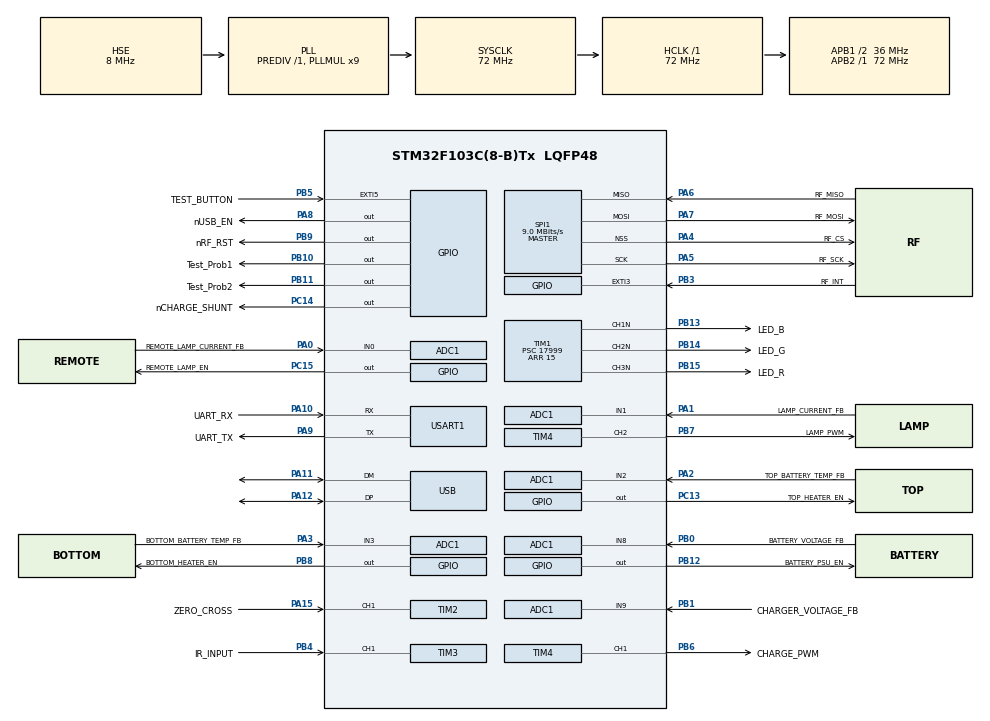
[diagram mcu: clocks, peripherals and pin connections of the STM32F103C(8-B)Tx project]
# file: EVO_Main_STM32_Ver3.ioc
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ADC1.Channel-0\#ChannelRegularConversion=ADC_CHANNEL_0
ADC1.Channel-1\#ChannelRegularConversion=ADC_CHANNEL_1
ADC1.Channel-2\#ChannelRegularConversion=ADC_CHANNEL_2
ADC1.Channel-3\#ChannelRegularConversion=ADC_CHANNEL_3
ADC1.Channel-4\#ChannelRegularConversion=ADC_CHANNEL_8
ADC1.Channel-5\#ChannelRegularConversion=ADC_CHANNEL_9
ADC1.ContinuousConvMode=ENABLE
ADC1.DiscontinuousConvMode=DISABLE
ADC1.NbrOfConversion=6
ADC1.NbrOfConversionFlag=1
ADC1.Rank-0\#ChannelRegularConversion=1
ADC1.Rank-1\#ChannelRegularConversion=2
ADC1.Rank-2\#ChannelRegularConversion=3
ADC1.Rank-3\#ChannelRegularConversion=4
ADC1.Rank-4\#ChannelRegularConversion=5
ADC1.Rank-5\#ChannelRegularConversion=6
ADC1.SamplingTime-0\#ChannelRegularConversion=ADC_SAMPLETIME_55CYCLES_5
ADC1.SamplingTime-1\#ChannelRegularConversion=ADC_SAMPLETIME_55CYCLES_5
ADC1.SamplingTime-2\#ChannelRegularConversion=ADC_SAMPLETIME_55CYCLES_5
ADC1.SamplingTime-3\#ChannelRegularConversion=ADC_SAMPLETIME_55CYCLES_5
ADC1.SamplingTime-4\#ChannelRegularConversion=ADC_SAMPLETIME_55CYCLES_5
ADC1.SamplingTime-5\#ChannelRegularConversion=ADC_SAMPLETIME_55CYCLES_5
ADC1.master=1
Dma.ADC1.0.Direction=DMA_PERIPH_TO_MEMORY
Dma.ADC1.0.Instance=DMA1_Channel1
Dma.ADC1.0.MemDataAlignment=DMA_MDATAALIGN_WORD
Dma.ADC1.0.MemInc=DMA_MINC_ENABLE
Dma.ADC1.0.Mode=DMA_CIRCULAR
Dma.ADC1.0.PeriphDataAlignment=DMA_PDATAALIGN_WORD
Dma.ADC1.0.PeriphInc=DMA_PINC_DISABLE
Dma.ADC1.0.Priority=DMA_PRIORITY_HIGH
Dma.Request0=ADC1
Mcu.Family=STM32F1
Mcu.Name=STM32F103C(8-B)Tx
Mcu.Package=LQFP48
NVIC.EXTI3_IRQn=true\:1\:0\:true\:false\:true\:true\:true\:true
NVIC.EXTI9_5_IRQn=true\:2\:0\:true\:false\:true\:true\:true\:true
NVIC.PriorityGroup=NVIC_PRIORITYGROUP_4
NVIC.TIM2_IRQn=true\:0\:0\:true\:false\:true\:true\:true\:true
NVIC.TIM3_IRQn=true\:1\:0\:true\:false\:true\:true\:true\:true
NVIC.USB_HP_CAN1_TX_IRQn=true\:1\:0\:true\:false\:true\:true\:true\:true
NVIC.USB_LP_CAN1_RX0_IRQn=true\:1\:0\:true\:false\:true\:false\:true\:true
PA0-WKUP.GPIO_Label=REMOTE_LAMP_CURRENT_FB
PA0-WKUP.Signal=ADCx_IN0
PA1.GPIO_Label=LAMP_CURRENT_FB
PA1.Signal=ADCx_IN1
PA10.GPIO_Label=UART_RX
PA10.Mode=Asynchronous
PA10.Signal=USART1_RX
PA11.Mode=Device
PA11.Signal=USB_DM
PA12.Mode=Device
PA12.Signal=USB_DP
PA13.Mode=Serial_Wire
PA13.Signal=SYS_JTMS-SWDIO
PA14.Mode=Serial_Wire
PA14.Signal=SYS_JTCK-SWCLK
PA15.GPIO_Label=ZERO_CROSS
PA15.GPIO_PuPd=GPIO_PULLUP
PA15.Signal=S_TIM2_CH1_ETR
PA2.GPIO_Label=TOP_BATTERY_TEMP_FB
PA2.Signal=ADCx_IN2
PA3.GPIO_Label=BOTTOM_BATTERY_TEMP_FB
PA3.Signal=ADCx_IN3
PA4.GPIO_Label=RF_CS
PA4.Mode=NSS_Signal_Hard_Output
PA4.Signal=SPI1_NSS
PA5.GPIO_Label=RF_SCK
PA5.Mode=Full_Duplex_Master
PA5.Signal=SPI1_SCK
PA6.GPIO_Label=RF_MISO
PA6.Mode=Full_Duplex_Master
PA6.Signal=SPI1_MISO
PA7.GPIO_Label=RF_MOSI
PA7.Mode=Full_Duplex_Master
PA7.Signal=SPI1_MOSI
PA8.GPIO_Label=nUSB_EN
PA8.Signal=GPIO_Output
PA9.GPIO_Label=UART_TX
PA9.Mode=Asynchronous
PA9.Signal=USART1_TX
PB0.GPIO_Label=BATTERY_VOLTAGE_FB
PB0.Signal=ADCx_IN8
PB1.GPIO_Label=CHARGER_VOLTAGE_FB
PB1.Signal=ADCx_IN9
PB10.GPIO_Label=Test_Prob1
PB10.GPIO_Speed=GPIO_SPEED_FREQ_MEDIUM
PB10.Signal=GPIO_Output
PB11.GPIO_Label=Test_Prob2
PB11.GPIO_Speed=GPIO_SPEED_FREQ_MEDIUM
PB11.Signal=GPIO_Output
PB12.GPIO_Label=BATTERY_PSU_EN
PB12.Signal=GPIO_Output
PB13.GPIO_Label=LED_B
PB13.Mode=PWM Generation1 CH1N
PB13.Signal=TIM1_CH1N
PB14.GPIO_Label=LED_G
PB14.Mode=PWM Generation2 CH2N
PB14.Signal=TIM1_CH2N
PB15.GPIO_Label=LED_R
PB15.Mode=PWM Generation3 CH3N
PB15.Signal=TIM1_CH3N
PB3.GPIO_Label=RF_INT
PB3.Signal=GPXTI3
PB4.GPIO_Label=IR_INPUT
PB4.Signal=S_TIM3_CH1
PB5.GPIO_Label=TEST_BUTTON
PB5.GPIO_ModeDefaultEXTI=GPIO_MODE_IT_FALLING
PB5.Signal=GPXTI5
PB6.GPIO_Label=CHARGE_PWM
PB6.GPIO_Speed=GPIO_SPEED_FREQ_MEDIUM
PB6.Signal=S_TIM4_CH1
PB7.GPIO_Label=LAMP_PWM
PB7.GPIO_Speed=GPIO_SPEED_FREQ_MEDIUM
PB7.Signal=S_TIM4_CH2
PB8.GPIO_Label=BOTTOM_HEATER_EN
PB8.Signal=GPIO_Output
PB9.GPIO_Label=nRF_RST
PB9.Signal=GPIO_Output
PC13-TAMPER-RTC.GPIO_Label=TOP_HEATER_EN
PC13-TAMPER-RTC.GPIO_PuPd=GPIO_PULLDOWN
PC13-TAMPER-RTC.Signal=GPIO_Output
PC14-OSC32_IN.GPIO_Label=nCHARGE_SHUNT
PC14-OSC32_IN.GPIO_PuPd=GPIO_PULLDOWN
PC14-OSC32_IN.Signal=GPIO_Output
PC15-OSC32_OUT.GPIO_Label=REMOTE_LAMP_EN
PC15-OSC32_OUT.GPIO_PuPd=GPIO_PULLDOWN
PC15-OSC32_OUT.Signal=GPIO_Output
PD0-OSC_IN.Mode=HSE-External-Oscillator
PD0-OSC_IN.Signal=RCC_OSC_IN
PD1-OSC_OUT.Mode=HSE-External-Oscillator
PD1-OSC_OUT.Signal=RCC_OSC_OUT
ProjectManager.HeapSize=0x200
ProjectManager.StackSize=0x400
ProjectManager.TargetToolchain=MDK-ARM V5
RCC.ADCPresc=RCC_ADCPCLK2_DIV6
RCC.AHBFreq_Value=72000000
RCC.APB1CLKDivider=RCC_HCLK_DIV2
RCC.APB1Freq_Value=36000000
RCC.APB1TimFreq_Value=72000000
RCC.APB2Freq_Value=72000000
RCC.APB2TimFreq_Value=72000000
RCC.HCLKFreq_Value=72000000
RCC.PLLMUL=RCC_PLL_MUL9
RCC.SYSCLKFreq_VALUE=72000000
RCC.SYSCLKSource=RCC_SYSCLKSOURCE_PLLCLK
RCC.USBFreq_Value=48000000
RCC.USBPrescaler=RCC_USBCLKSOURCE_PLL_DIV1_5
SH.ADCx_IN0.0=ADC1_IN0,IN0
SH.ADCx_IN1.0=ADC1_IN1,IN1
SH.ADCx_IN2.0=ADC1_IN2,IN2
SH.ADCx_IN3.0=ADC1_IN3,IN3
SH.ADCx_IN8.0=ADC1_IN8,IN8
SH.ADCx_IN9.0=ADC1_IN9,IN9
SH.S_TIM2_CH1_ETR.0=TIM2_CH1,Input_Capture1_from_TI1
SH.S_TIM3_CH1.0=TIM3_CH1,Input_Capture1_from_TI1
SH.S_TIM4_CH1.0=TIM4_CH1,PWM Generation1 CH1
SH.S_TIM4_CH2.0=TIM4_CH2,PWM Generation2 CH2
SPI1.BaudRatePrescaler=SPI_BAUDRATEPRESCALER_8
SPI1.CalculateBaudRate=9.0 MBits/s
SPI1.Direction=SPI_DIRECTION_2LINES
SPI1.Mode=SPI_MODE_MASTER
SPI1.VirtualNSS=VM_NSSHARD
SPI1.VirtualType=VM_MASTER
TIM1.AutoReloadPreload=TIM_AUTORELOAD_PRELOAD_ENABLE
TIM1.Channel-PWM\ Generation1\ CH1N=TIM_CHANNEL_1
TIM1.Channel-PWM\ Generation2\ CH2N=TIM_CHANNEL_2
TIM1.Channel-PWM\ Generation3\ CH3N=TIM_CHANNEL_3
TIM1.OC1Preload_PWM=ENABLE
TIM1.OCNIdleState_1=TIM_OCNIDLESTATE_SET
TIM1.OCNIdleState_2=TIM_OCNIDLESTATE_SET
TIM1.OCNIdleState_3=TIM_OCNIDLESTATE_SET
TIM1.OCNPolarity_1=TIM_OCNPOLARITY_LOW
TIM1.OCNPolarity_2=TIM_OCNPOLARITY_LOW
TIM1.OCNPolarity_3=TIM_OCNPOLARITY_LOW
TIM1.Period=15
TIM1.Prescaler=17999
TIM2.AutoReloadPreload=TIM_AUTORELOAD_PRELOAD_DISABLE
TIM2.Channel-Input_Capture1_from_TI1=TIM_CHANNEL_1
TIM2.Channel-Input_Capture2_from_TI1_63=TIM_CHANNEL_2
TIM2.ICFilter_CH1=8
TIM2.ICPolarity_CH1=TIM_INPUTCHANNELPOLARITY_FALLING
TIM2.ICPrescaler-Input_Capture1_from_TI1=TIM_ICPSC_DIV1
TIM2.Period=65535
TIM2.Prescaler=143
TIM2.TIM_MasterOutputTrigger=TIM_TRGO_RESET
TIM3.Channel-Input_Capture1_from_TI1=TIM_CHANNEL_1
TIM3.Channel-Input_Capture2_from_TI1_63=TIM_CHANNEL_2
TIM3.ICPolarity_CH1=TIM_INPUTCHANNELPOLARITY_FALLING
TIM3.Period=40000
TIM3.Prescaler=71
TIM4.AutoReloadPreload=TIM_AUTORELOAD_PRELOAD_ENABLE
TIM4.Channel-PWM\ Generation1\ CH1=TIM_CHANNEL_1
TIM4.Channel-PWM\ Generation2\ CH2=TIM_CHANNEL_2
TIM4.OCPolarity_1=TIM_OCPOLARITY_HIGH
TIM4.OCPolarity_2=TIM_OCPOLARITY_HIGH
TIM4.Period=99
TIM4.Prescaler=359
USART1.VirtualMode=VM_ASYNC
USB_DEVICE.CLASS_NAME_FS=CDC
USB_DEVICE.PID_CDC_FS=0x5740
USB_DEVICE.VID=0x483
USB_DEVICE.VirtualMode=Cdc
USB_DEVICE.VirtualModeFS=Cdc_FS
VP_TIM1_VS_ClockSourceINT.Mode=Internal
VP_TIM2_VS_ClockSourceINT.Mode=Internal
VP_TIM2_VS_indirect_ch1.Mode=Input_Capture2_from_TI1_63
VP_TIM3_VS_ClockSourceINT.Mode=Internal
VP_TIM3_VS_indirect_ch1.Mode=Input_Capture2_from_TI1_63
VP_TIM4_VS_ClockSourceINT.Mode=Internal
VP_USB_DEVICE_VS_USB_DEVICE_CDC_FS.Mode=CDC_FS
board=custom

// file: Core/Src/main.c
/* USER CODE BEGIN Header */
/**
  ******************************************************************************
  * @file           : main.c
  * @brief          : Main program body
  ******************************************************************************
  * @attention
  *
  * Copyright (c) 2023 STMicroelectronics.
  * All rights reserved.
  *
  * This software is licensed under terms that can be found in the LICENSE file
  * in the root directory of this software component.
  * If no LICENSE file comes with this software, it is provided AS-IS.
  *
  ******************************************************************************
  */
/* USER CODE END Header */
#include "main.h"
#include "usb_device.h"

/* USER CODE BEGIN Includes */
#include "usbd_cdc_if.h"
#include "Flash_EEPROM.h"
#include "IR_Zero_Cross.h"
#include "Charge.h"
#include "ADC.h"
#include "stm32f1xx_it.h"

//#include "stm32f1xx_hal_tim.h"

/* USER CODE END Includes */

/* USER CODE BEGIN PD */
#define ADDR_FLASH_SECTOR_63     ((uint32_t)0x0800FC00)  /* Base address of Sector 63, 1 Kbytes  */
#define FLASH_MEMORY_ADDR         ADDR_FLASH_SECTOR_63

/*
#define Seconds_Per_Day          	86400         // should be 86400-1 *nan
#define Days_Per_Period           28            // should be 28 days *nan
#define Long_Test_Period_Num 		  13            // should be 13: total of 13 period *nan
*/

#define AC_Fail                  	0
#define AC_Good                 	1
#define Invalid							      2

/* USER CODE END PD */

ADC_HandleTypeDef hadc1;
DMA_HandleTypeDef hdma_adc1;

SPI_HandleTypeDef hspi1;

TIM_HandleTypeDef htim1;
TIM_HandleTypeDef htim2;
TIM_HandleTypeDef htim3;
TIM_HandleTypeDef htim4;

UART_HandleTypeDef huart1;

/* USER CODE BEGIN PV */
extern LED_Profile_TypeDef  *Pointer_Profile_running;

extern uint16_t time_stamp_start;
extern uint16_t Emergency_ElapsedTime;

uint32_t Time_delay_Elapsed;
uint32_t Time_delay_StartTime;

System_State_TypeDef System_State_Machine = STANDBY;

struct sys_time System_time ={0,0,27,0}; // day:27 is for UL test -> 24hours later to start the short test

uint8_t Short_test_En = 0;
uint8_t Long_test_En  = 0;

NV_Profile_TypeDef NV_Profile_Default =
{
  1,
  0x2e782dade227f669,         //signature
  16,             			// Total wattage of the unit, optianl of 16W,32W and 64W(battery realted)
  8,            			// Lamp head wattage: 4W, 8W and 16W
  0,               			// heater installation
  1,						// Self test enable
  0,          			     // Delay after AC resumed, uint: seconds, options - 0s 0r 900s
  0,                          // the last testing failure flag
  200,                        // default lamp current value for the first time programming (4W value)
  200,                        // default lamp current value for the first time programming (4W value)
 };

extern LED_Profile_TypeDef LED_Profile_90M_TEST;
extern LED_Profile_TypeDef LED_Profile_30s_TEST;
extern LED_Profile_TypeDef LED_Profile_Batt_Disconnect;
extern LED_Profile_TypeDef LED_Profile_Charger_Fail;
extern LED_Profile_TypeDef LED_Profile_Lamp_Fail;
extern LED_Profile_TypeDef LED_Profile_Low_Capacity;
extern LED_Profile_TypeDef LED_Profile_Emergency;
extern LED_Profile_TypeDef LED_Profile_Heating;
extern LED_Profile_TypeDef LED_Profile_Fast_Charge;
extern LED_Profile_TypeDef LED_Profile_Full_Float_Charge;

int32_t  ChargerTest_VoltRaised =0;   // voltage increas amount during the testing period
uint8_t  Charg_Current_Percentage =0; // 0-99 for PWM value backup to resume the charging current
extern CHR_TypeDef CHR_Stage;
extern uint32_t Charger_StartTime ;
extern uint32_t Charger_ElapsedTime;
extern uint8_t Charge_rate;

uint32_t ADC_StartTime =0;               // for ADC sampling time gap, unit: millisecond
uint32_t ADC_CurrentTime =0;
uint32_t ADC_ElapsedTime =0;

uint32_t ADC_Local_lamp_FB_init;         //local lamp current measured when power up for diagnostic
uint32_t ADC_Remote_lamp_FB_init;

uint32_t ADC_Local_lamp_FB_reading;      //local lamp current reading when diagnostic
uint32_t ADC_Remote_lamp_FB_reading;

// For diming
uint8_t  Lamp_Diming_level;              // the lamp brightness PWM control for diming, decreaed by 1 on each time
uint8_t  Lamp_Diming_timer;              // the timing for emergency diming time period, diming level decreaes when timer count down to zero
uint8_t  Lamp_Diming_cnt;                // the decreasing times during the diming period of 16 min

uint16_t Lamp_Diming_startTime;
uint8_t  Lamp_Dimng_elapsedTime;

extern uint32_t ADC_batt_reading;
extern uint32_t ADC_charger_reading;

extern uint32_t ADC_DMA_VALUE[6];
extern uint32_t ADC_CHANNCEL_VAL;

extern void ADC_BATT_CHR_ACQ(void);

Heater_state_TypeDef Heater_state[2] = {Heater_Off}; // [0]: buttom heater, [1]: top heater

ButtonPressType_TypeDef TEST_Button = Idle;
//Button_State_TypeDef Button_State = Button_Release;

uint32_t ADC_temp_reading[2];                        // temperature ADC value reading buffer, [0]: buttom , [1]: top

/* USER CODE END PV */

void SystemClock_Config(void);
static void MX_GPIO_Init(void);
static void MX_DMA_Init(void);
static void MX_ADC1_Init(void);
static void MX_SPI1_Init(void);
static void MX_TIM1_Init(void);
static void MX_TIM2_Init(void);
static void MX_TIM3_Init(void);
static void MX_TIM4_Init(void);
static void MX_USART1_UART_Init(void);
/* USER CODE BEGIN PFP */
extern void Flash_write(void);
extern void Flash_read(void);
extern void Flash_clear(void);
extern HAL_StatusTypeDef HAL_TIM_Base_Start_IT(TIM_HandleTypeDef *htim);

NV_Profile_TypeDef NV_Profile_Runtime;

uint32_t time_delta(uint32_t Current_time, uint32_t start_time);  // for calculate the time duration of seconds or minutes

extern void LED_task(LED_Display_TypeDef Display_Type, FunctionalState Enable);
extern void IR_task(void);
extern uint8_t Zero_Cross_Task(void);

/* USER CODE END PFP */

/* USER CODE BEGIN 0 */

//USB init and reset
void USB_Init(void)   // added USB reset
{

    GPIO_InitTypeDef GPIO_InitStruct = {0};
    __HAL_RCC_GPIOA_CLK_ENABLE();

    HAL_GPIO_WritePin(GPIOA,  GPIO_PIN_11 | GPIO_PIN_12, GPIO_PIN_RESET);
    GPIO_InitStruct.Pin = GPIO_PIN_11 | GPIO_PIN_12;
    GPIO_InitStruct.Mode = GPIO_MODE_OUTPUT_PP;
    GPIO_InitStruct.Pull = GPIO_PULLDOWN;
    GPIO_InitStruct.Speed = GPIO_SPEED_FREQ_LOW;
    HAL_GPIO_Init(GPIOA, &GPIO_InitStruct);

    HAL_Delay(20);

}

 uint8_t Remote_Lamp_Flag =0;

// Lamp init

void LAMP_Init(void)
{
  if (ADC_DMA_VALUE[ADC_BATT_VOLTAGE] < V_PreChr )   // under low battery voltage condition, don't read the lamp current, get the saved value from Flash memory instead.
  {
    ADC_Local_lamp_FB_init  = NV_Profile_Runtime.LocalLampCurrentInit;
    ADC_Remote_lamp_FB_init = NV_Profile_Runtime.RemoteLampCurrentInit;
  }
  else                                              // battery voltage is good for lamp initialze,
  {
    Lamp_ctrl(ENABLE, NV_Profile_Runtime.HeadWattage); // turn on local lamp
    Remote_Lamp_EN(ENABLE);                            // turn on remote lamp

    HAL_Delay(1500);         // keep the lamp on for virtual checking

    uint8_t i =0;
    ADC_Local_lamp_FB_init =0;
    for (i=0; i < ADC_slide_windows_size; i++)              // measure local lamp current
    {
      ADC_Local_lamp_FB_init += ADC_DMA_VALUE[ADC_LOCAL_LAMP_CUR];
      HAL_Delay(2);
    }

    ADC_Local_lamp_FB_init = ADC_Local_lamp_FB_init/ADC_slide_windows_size;     //ADC_DMA_VALUE[ADC_LOCAL_LAMP_CUR];
    if (ADC_Local_lamp_FB_init < 120)                                           // 60% of ADC value 200 (4W)
    {
	 ADC_Local_lamp_FB_init = 0; // no lamp detected, clear the current value
    }

    NV_Profile_Runtime.LocalLampCurrentInit = ADC_Local_lamp_FB_init;           // update the flash memory value

    for (i=0; i< ADC_slide_windows_size; i++)              // measure remote lamp current
    {
	 ADC_Remote_lamp_FB_init += ADC_DMA_VALUE[ADC_REMOTE_LAMP_CUR];
	 HAL_Delay(2);
    }
    ADC_Remote_lamp_FB_init = ADC_Remote_lamp_FB_init/ADC_slide_windows_size;  // ADC_DMA_VALUE[ADC_REMOTE_LAMP_CUR];
    if (ADC_Remote_lamp_FB_init < 120)                                         // 60% of ADC value 200 (4W)
    {
	 ADC_Remote_lamp_FB_init = 0;                                             // no lamp detected, clear the current value
    }

    NV_Profile_Runtime.RemoteLampCurrentInit = ADC_Remote_lamp_FB_init;        // update the flash memory value

    Lamp_ctrl(DISABLE, 0);      // turn off the lamps
    Remote_Lamp_EN(DISABLE);
    Flash_write();  // update flasg

  }

/*
	 if (ADC_Local_lamp_FB_init < 150)   // 75% of ADC value 200 (4W)
	 {
	   Local_Lamp_Flag = 0;              // this flag indicate if there is lamp installed-> 0: not installed; 1:installed
	   ADC_Local_lamp_FB_init = 0;
	 }
	 else
	 {
	   Local_Lamp_Flag = 1;
	 }
*/
  if (ADC_Remote_lamp_FB_init < 150)  // 75% of ADC value 200 (4W)
  {
    Remote_Lamp_Flag = 0;             // remote lamp not installed
    ADC_Remote_lamp_FB_init =0;
  }
  else
  {
    Remote_Lamp_Flag = 1;
  }

}

void Charger_Init(void)
{
  uint8_t watt = NV_Profile_Runtime.UnitWattage;

  switch (watt)
  {
    case 16:
    {
      Charge_rate = Chr_Rate_Small_Batt;

      break;
    }
    case 32:
    {
      Charge_rate = Chr_Rate_Big_Batt;

      break;
    }
    case 64:
    {
      Charge_rate = Chr_Rate_Big_Batt *2;

      break;
    }
    default:
      break;
  }

}

/* USER CODE END 0 */

int main(void)
{
// changes test

  /* MCU Configuration--------------------------------------------------------*/

  /* Reset of all peripherals, Initializes the Flash interface and the Systick. */
   HAL_Init();

  /* Configure the system clock */
  SystemClock_Config();

  /* USER CODE BEGIN SysInit */

	 USB_Init();

  /* USER CODE END SysInit */

  /* Initialize all configured peripherals */
  MX_GPIO_Init();
  MX_DMA_Init();
  MX_ADC1_Init();
  MX_SPI1_Init();
  MX_TIM1_Init();
  MX_TIM2_Init();
  MX_TIM3_Init();
  MX_TIM4_Init();
  MX_USB_DEVICE_Init();
  MX_USART1_UART_Init();
  /* USER CODE BEGIN 2 */

// ---------- USB init -----------------

  HAL_GPIO_WritePin(nUSB_EN_GPIO_Port,nUSB_EN_Pin,GPIO_PIN_RESET);              //Enable USB : pull up DP
  HAL_GPIO_WritePin(BATTERY_PSU_EN_GPIO_Port,BATTERY_PSU_EN_Pin,GPIO_PIN_SET);  //Enable battery power

// ------------ LED PWM Init ---------------------

	HAL_TIMEx_PWMN_Start(&htim1,TIM_CHANNEL_1);	//Enable  LED PWM Channels
	HAL_TIMEx_PWMN_Start(&htim1,TIM_CHANNEL_2);
	HAL_TIMEx_PWMN_Start(&htim1,TIM_CHANNEL_3);

//------------- lamp PWM init --------------

  HAL_TIM_PWM_Start(&htim4,TIM_CHANNEL_2);  // Enable Lamp PWM

// ----------- zero cross capture init ----------

    HAL_TIM_Base_Start_IT(&htim2);
    HAL_TIM_IC_Start_IT(&htim2,TIM_CHANNEL_1);  //start zero croess duty cycle capture
		HAL_TIM_IC_Start_IT(&htim2,TIM_CHANNEL_2);

// ----------- IR capture init ----------
		HAL_TIM_Base_Start_IT(&htim3);              // start IR remote capture
    HAL_TIM_IC_Start_IT(&htim3,TIM_CHANNEL_1);
		HAL_TIM_IC_Start_IT(&htim3,TIM_CHANNEL_2);
    HAL_Delay(20);

// ----------- Charge PWM init ----------

    HAL_GPIO_WritePin(nCHARGE_SHUNT_GPIO_Port,nCHARGE_SHUNT_Pin,GPIO_PIN_RESET);  // enable shunt resister
    HAL_TIM_PWM_Start(&htim4,TIM_CHANNEL_1);	                                    //Enable  charge PWM

// ------------ ADC init -------------

	HAL_ADCEx_Calibration_Start(&hadc1);          // ADC calibration
	HAL_ADC_Start_DMA(&hadc1, ADC_DMA_VALUE, 6 ); // start ADC

// load profile

	memcpy (&NV_Profile_Runtime,(uint32_t*)FLASH_MEMORY_ADDR, sizeof(NV_Profile_Runtime)); // load  profile from Flash Memory to ram
	if ( NV_Profile_Runtime.Flag == 0xFF )                    // check if the flash memory is blank
	{
  	  memcpy (&NV_Profile_Runtime, &NV_Profile_Default, sizeof(NV_Profile_Runtime)); //the FLASH is blank, load default and save to the flash, this will occure only the first time running the code at factory
       Flash_write();  // save the profile data from runtime ram to flash
      }

	__HAL_TIM_SetCompare(&htim1, LED_PWM_CH_RED, LED_LUMNOUS);
	__HAL_TIM_SetCompare(&htim1, LED_PWM_CH_GREEN, LED_LUMNOUS);
	__HAL_TIM_SetCompare(&htim1, LED_PWM_CH_BLUE, LED_LUMNOUS);

	ADC_BATT_CHR_ACQ();

	// lamp init, measure the Lamp current as reference for diagnostic
	LAMP_Init();

	if (NV_Profile_Runtime.LastTestFailedFlag == 1)
	{
	  LED_task(Low_Capacity, ENABLE);  // indicate the batter was fail on the last Long Test
	}

     BATT_TEMP_task();

// Charger init, load the charge rate for battery configurations

     Charger_Init();

	CHARGE_task();

  /* USER CODE END 2 */

  /* Infinite loop */
  /* USER CODE BEGIN WHILE */

 while (1)
 {
 /*
	USBVcom_printf("ms: %llu\r\n", System_time.ms);
	HAL_Delay(1);
	USBVcom_printf("Second: %u\r\n", System_time.Sec);
	HAL_Delay(1);
	USBVcom_printf("Day: %hu\r\n\r\n", System_time.Day);
 */

  switch (System_State_Machine)
  {
    case STANDBY:   // standby mode
    {

	 LED_Driver();

	 if (Zero_Cross_Task() == AC_Fail )
	 {

	   Lamp_ctrl(ENABLE, NV_Profile_Runtime.HeadWattage);
	   Remote_Lamp_EN(ENABLE);

	   HAL_Delay(200);

	   time_stamp_start = System_time.Sec; // emergency timer start
	   System_State_Machine = EMERGENCY;   // has to excute this before disable the heaters for proventing the heater state machine go into the heating stage

	   LED_task(Emergency, ENABLE);
	   ADC_StartTime = HAL_GetTick();     // start ADC timer
	   Charger_ElapsedTime =0;

        break;
	 }

	 BATT_TEMP_task();   // check the battery temperature, has to be done prior to the CHARGE_Task because it need to report the temperature that used for Charge

      ADC_BATT_CHR_ACQ();

	 CHARGE_task();      // check and auto control the battery charge

	 HEATER_task();
	 Button_task();      // check the button and start the test mode

	 if (NV_Profile_Runtime.SelfDiagnosticEnabled != 0)
	 {
	   Scheduler_task();
	 }

	 IR_task();          // check the IR remote command

	 break;
    }

    case EMERGENCY:
    {
	 ADC_ElapsedTime = ElapsedTimer_ADC(ADC_StartTime);           // ADC timing
      if(System_time.Sec < time_stamp_start)                       // Emergency duration timing
	 {
	   Emergency_ElapsedTime = UINT32_MAX/1000 + System_time.Sec - time_stamp_start +1;
	 }
	 else
	 {
	   Emergency_ElapsedTime = System_time.Sec - time_stamp_start;
	 }

	 if (( (ADC_ElapsedTime)%1500 == 0) && ADC_ElapsedTime > 1499)   //every 1.5s to read the ADC
	 {
//	   ADC_batt_reading = ADC_DMA_VALUE[ADC_BATT_VOLTAGE];

	   if ( ADC_batt_reading < V_Low_Temp )
	   {
	    Lamp_ctrl(DISABLE, 0);                                                          // turn off the MCU and the lamps when the battery is too low
	    HAL_GPIO_WritePin(BATTERY_PSU_EN_GPIO_Port,BATTERY_PSU_EN_Pin,GPIO_PIN_RESET);  //Disable power from battery to system
	   }

	   ADC_StartTime = HAL_GetTick() ;   //reload the start time for the next 1.5 Sec delay
	 }

	 Lamp_Diming();

      if (Zero_Cross_Task() == AC_Good )
	 {
        Time_delay_Elapsed = ElapsedTimer_TimeDelay( Time_delay_StartTime );;
//	   ADC_batt_reading = ADC_DMA_VALUE[ADC_BATT_VOLTAGE]; //

	   if( Time_delay_Elapsed > NV_Profile_Runtime.TimeDelayPeriod)
	   {
	     Lamp_ctrl(DISABLE, 0);                               // turn off the lamps return to standby
  	     Remote_Lamp_EN(DISABLE);

          LED_task(Emergency, DISABLE);
          CHR_Stage = IDL_CHR;

	     if ((Short_test_En == 1) || ( Long_test_En == 1))   //  when emergency duration is over the short test or long test schedule, delay 1 day.
	     {
		  System_time.Sec = 0;
		  System_time.Day = 27;
		  Short_test_En = 0;
		  Long_test_En = 0;
	     }

	     System_State_Machine = STANDBY;
	     HAL_Delay(10);
	     Charger_ElapsedTime = 0;
	     Charger_StartTime = HAL_GetTick();        //load the start time for the charger timer

	     break;
        }
	 }
	 else Time_delay_StartTime = HAL_GetTick(); // reset the start time of the Time_Delay timer

	 ADC_BATT_CHR_ACQ();
	 CHARGE_task();
	 LED_Driver();
	 break;
    }

    case SHORT_TEST:
    {
      ADC_ElapsedTime = ElapsedTimer_ADC(ADC_StartTime);
      ADC_BATT_CHR_ACQ();

	 if (( (ADC_ElapsedTime%1000) <= 9) && ADC_ElapsedTime > 950)   //every 1.0s to measure the ADC
	 {
	   if ( ADC_batt_reading < V_PreChr)                //
	   {
		 LED_task(Batt_Disconnect, ENABLE);
	   }
	   else
	   {
		 LED_task(Batt_Disconnect, DISABLE);

		 ADC_Local_lamp_FB_reading = ADC_DMA_VALUE[ADC_LOCAL_LAMP_CUR];

		 ADC_Remote_lamp_FB_reading = ADC_DMA_VALUE[ADC_REMOTE_LAMP_CUR];

		 if ( ADC_batt_reading < V_PreChr)      // turn off the lamps when the battery is dead
		 {
		   LED_task(Batt_Disconnect, ENABLE);
		 }

		 if ( (ADC_Local_lamp_FB_reading < (3*ADC_Local_lamp_FB_init/4)) || (ADC_Remote_lamp_FB_reading < (3*ADC_Remote_lamp_FB_init/4)) ) // check if the current is greater than 75% of the normal lamp current
		 {
		   LED_task(Lamp_Fail, ENABLE);
		 }
		 else
		 {
		   LED_task(Lamp_Fail, DISABLE);
		 }
	   }

	   ADC_StartTime = HAL_GetTick() ;   //reload the start time for the nest 2s delay
	 }

	 if( time_delta(System_time.Sec,time_stamp_start) >= 30 )                    // 30 for 30 second test
	 {
	   Lamp_ctrl(DISABLE, 0);  // turn off the lamps return to standby
  	   Remote_Lamp_EN(DISABLE);
	   TEST_Button = Idle;

	   LED_task(_30s_TEST, DISABLE);
	   Charger_ElapsedTime = 0;
	   System_State_Machine = STANDBY;
	 }

	 CHARGE_task();
      IR_task();

	 Button_task();
	 LED_Driver();

	 break;
    }

    case LONG_TEST:
    {
	 ADC_ElapsedTime = ElapsedTimer_ADC(ADC_StartTime);
	 if(System_time.Sec < time_stamp_start)                       // Long test duration timing using the emergency timer
	 {
	   Emergency_ElapsedTime = UINT32_MAX/1000 + System_time.Sec - time_stamp_start +1;
	 }
	 else
	 {
	   Emergency_ElapsedTime = System_time.Sec - time_stamp_start;
	 }

	 if (( (ADC_ElapsedTime%1000) <= 9) && ADC_ElapsedTime > 950)   //every 1.0s to measure the ADC
	 {
	   if ( ADC_batt_reading < V_PreChr)                //
	   {
		 LED_task(Batt_Disconnect, ENABLE);
	   }
	   else
	   {
		 LED_task(Batt_Disconnect, DISABLE);

		 ADC_Local_lamp_FB_reading = ADC_DMA_VALUE[ADC_LOCAL_LAMP_CUR];  // read the lamp current from ADC
		 if (Emergency_ElapsedTime < DIMING_START_TIME )                 // before diming start, take 75% for the check threshold
		 {
		   if( ADC_Local_lamp_FB_reading < (3*ADC_Local_lamp_FB_init/4))   // check to see if the current is greater than 75% of the normal lamp current
			  LED_task(Lamp_Fail, ENABLE);
		   else
			  LED_task(Lamp_Fail, DISABLE);
		 }
		 else // after the diming started, take 50% for the check threshold
		 {
		   if(ADC_Local_lamp_FB_reading < (ADC_Local_lamp_FB_init/2))   // check to see if the current is greater than 50% of the normal lamp current
			 LED_task(Lamp_Fail, ENABLE);
		   else
			 LED_task(Lamp_Fail, DISABLE);
		 }

		 ADC_Remote_lamp_FB_reading = ADC_DMA_VALUE[ADC_REMOTE_LAMP_CUR]; // read the lamp current from ADC
		 if (Emergency_ElapsedTime < DIMING_START_TIME )                  // before diming start, take 75% for the check threshold
		 {
		   if( ADC_Remote_lamp_FB_reading < (3*ADC_Remote_lamp_FB_init/4))
		       LED_task(Lamp_Fail, ENABLE);
		   else
			  LED_task(Lamp_Fail, DISABLE);
		 }
		 else  // after the diming started, take 50% for the check threshold
		 {
		   if ( ADC_Remote_lamp_FB_reading < (ADC_Remote_lamp_FB_init/2)) // check to see if the current is greater than 50% of the normal lamp current
			   LED_task(Lamp_Fail, ENABLE);
		   else
			   LED_task(Lamp_Fail, DISABLE);
		 }

        }

	   ADC_StartTime = HAL_GetTick() ;   //reset the start time for the next 1s delay
	 }

	 if ( ADC_batt_reading < V_Low_Capacity )  // fail the 90M test before the 90M is due
	 {
	   Lamp_ctrl(DISABLE, 0);  // turn off the lamps return to standby
  	   Remote_Lamp_EN(DISABLE);

	   TEST_Button = Idle;
	   LED_task(Low_Capacity, ENABLE);
	   LED_task(_90M_TEST, DISABLE);
	   System_State_Machine = STANDBY;
      }
      else
	 {                                                                                 // pass the 90M test
	   if (time_delta(System_time.Sec, time_stamp_start) >= 5400)                      // should be 5400 for 90min test *nan
	   {
		Lamp_ctrl(DISABLE, 0);  // turn off the lamps return to standby
  	     Remote_Lamp_EN(DISABLE);

          TEST_Button = Idle;
		NV_Profile_Runtime.LastTestFailedFlag = 0;                                  //clear the fail flag
		Flash_write();

		LED_task(_90M_TEST, DISABLE);
		System_State_Machine = STANDBY;
	   }

	 }

	 Lamp_Diming();

      ADC_BATT_CHR_ACQ();
	 CHARGE_task();
	 IR_task();
	 Button_task();
	 LED_Driver();

	 break;
    }

    case EOL:
    {
	 break;
    }

    case DEMO:
    {

	 LED_Driver();
	 BATT_TEMP_task();   // check the battery temperature, has to be done prior to the CHARGE_Task because it need to report the temperature that used for Charge
      ADC_BATT_CHR_ACQ();

	 HEATER_task();

	 CHARGE_task();      // check and auto control the battery charge

	 Button_task();      // check the button and start the test mode
	 IR_task();
  	 break;
    }

    case SHIP:
    {

	 break;
    }

    default: break;
  }

// -------------------

	//	  USBVcom_printf("Freq:%f\r\n", AC_Freq);
//			USBVcom_printf("Duty:%f\r\n\r\n", Duty_Cycle);
//    printf("Duty:%.2f %% \r\n",(float)Duty_Cycle);
//		printf("Freq:%u\r\n", AC_Freq);

    /* USER CODE END WHILE */

  }
}

void SystemClock_Config(void)
{
  RCC_OscInitTypeDef RCC_OscInitStruct = {0};
  RCC_ClkInitTypeDef RCC_ClkInitStruct = {0};
  RCC_PeriphCLKInitTypeDef PeriphClkInit = {0};

  /** Initializes the RCC Oscillators according to the specified parameters
  * in the RCC_OscInitTypeDef structure.
  */
  RCC_OscInitStruct.OscillatorType = RCC_OSCILLATORTYPE_HSE;
  RCC_OscInitStruct.HSEState = RCC_HSE_ON;
  RCC_OscInitStruct.HSEPredivValue = RCC_HSE_PREDIV_DIV1;
  RCC_OscInitStruct.HSIState = RCC_HSI_ON;
  RCC_OscInitStruct.PLL.PLLState = RCC_PLL_ON;
  RCC_OscInitStruct.PLL.PLLSource = RCC_PLLSOURCE_HSE;
  RCC_OscInitStruct.PLL.PLLMUL = RCC_PLL_MUL9;
  if (HAL_RCC_OscConfig(&RCC_OscInitStruct) != HAL_OK)
  {
    Error_Handler();
  }

  /** Initializes the CPU, AHB and APB buses clocks
  */
  RCC_ClkInitStruct.ClockType = RCC_CLOCKTYPE_HCLK|RCC_CLOCKTYPE_SYSCLK
                              |RCC_CLOCKTYPE_PCLK1|RCC_CLOCKTYPE_PCLK2;
  RCC_ClkInitStruct.SYSCLKSource = RCC_SYSCLKSOURCE_PLLCLK;
  RCC_ClkInitStruct.AHBCLKDivider = RCC_SYSCLK_DIV1;
  RCC_ClkInitStruct.APB1CLKDivider = RCC_HCLK_DIV2;
  RCC_ClkInitStruct.APB2CLKDivider = RCC_HCLK_DIV1;

  if (HAL_RCC_ClockConfig(&RCC_ClkInitStruct, FLASH_LATENCY_2) != HAL_OK)
  {
    Error_Handler();
  }
  PeriphClkInit.PeriphClockSelection = RCC_PERIPHCLK_ADC|RCC_PERIPHCLK_USB;
  PeriphClkInit.AdcClockSelection = RCC_ADCPCLK2_DIV6;
  PeriphClkInit.UsbClockSelection = RCC_USBCLKSOURCE_PLL_DIV1_5;
  if (HAL_RCCEx_PeriphCLKConfig(&PeriphClkInit) != HAL_OK)
  {
    Error_Handler();
  }
}

static void MX_ADC1_Init(void)
{

  ADC_ChannelConfTypeDef sConfig = {0};

  /** Common config
  */
  hadc1.Instance = ADC1;
  hadc1.Init.ScanConvMode = ADC_SCAN_ENABLE;
  hadc1.Init.ContinuousConvMode = ENABLE;
  hadc1.Init.DiscontinuousConvMode = DISABLE;
  hadc1.Init.ExternalTrigConv = ADC_SOFTWARE_START;
  hadc1.Init.DataAlign = ADC_DATAALIGN_RIGHT;
  hadc1.Init.NbrOfConversion = 6;
  if (HAL_ADC_Init(&hadc1) != HAL_OK)
  {
    Error_Handler();
  }

  /** Configure Regular Channel
  */
  sConfig.Channel = ADC_CHANNEL_0;
  sConfig.Rank = ADC_REGULAR_RANK_1;
  sConfig.SamplingTime = ADC_SAMPLETIME_55CYCLES_5;
  if (HAL_ADC_ConfigChannel(&hadc1, &sConfig) != HAL_OK)
  {
    Error_Handler();
  }

  /** Configure Regular Channel
  */
  sConfig.Channel = ADC_CHANNEL_1;
  sConfig.Rank = ADC_REGULAR_RANK_2;
  if (HAL_ADC_ConfigChannel(&hadc1, &sConfig) != HAL_OK)
  {
    Error_Handler();
  }

  /** Configure Regular Channel
  */
  sConfig.Channel = ADC_CHANNEL_2;
  sConfig.Rank = ADC_REGULAR_RANK_3;
  if (HAL_ADC_ConfigChannel(&hadc1, &sConfig) != HAL_OK)
  {
    Error_Handler();
  }

  /** Configure Regular Channel
  */
  sConfig.Channel = ADC_CHANNEL_3;
  sConfig.Rank = ADC_REGULAR_RANK_4;
  if (HAL_ADC_ConfigChannel(&hadc1, &sConfig) != HAL_OK)
  {
    Error_Handler();
  }

  /** Configure Regular Channel
  */
  sConfig.Channel = ADC_CHANNEL_8;
  sConfig.Rank = ADC_REGULAR_RANK_5;
  if (HAL_ADC_ConfigChannel(&hadc1, &sConfig) != HAL_OK)
  {
    Error_Handler();
  }

  /** Configure Regular Channel
  */
  sConfig.Channel = ADC_CHANNEL_9;
  sConfig.Rank = ADC_REGULAR_RANK_6;
  if (HAL_ADC_ConfigChannel(&hadc1, &sConfig) != HAL_OK)
  {
    Error_Handler();
  }

}

static void MX_SPI1_Init(void)
{

  /* SPI1 parameter configuration*/
  hspi1.Instance = SPI1;
  hspi1.Init.Mode = SPI_MODE_MASTER;
  hspi1.Init.Direction = SPI_DIRECTION_2LINES;
  hspi1.Init.DataSize = SPI_DATASIZE_8BIT;
  hspi1.Init.CLKPolarity = SPI_POLARITY_LOW;
  hspi1.Init.CLKPhase = SPI_PHASE_1EDGE;
  hspi1.Init.NSS = SPI_NSS_HARD_OUTPUT;
  hspi1.Init.BaudRatePrescaler = SPI_BAUDRATEPRESCALER_8;
  hspi1.Init.FirstBit = SPI_FIRSTBIT_MSB;
  hspi1.Init.TIMode = SPI_TIMODE_DISABLE;
  hspi1.Init.CRCCalculation = SPI_CRCCALCULATION_DISABLE;
  hspi1.Init.CRCPolynomial = 10;
  if (HAL_SPI_Init(&hspi1) != HAL_OK)
  {
    Error_Handler();
  }

}

static void MX_TIM1_Init(void)
{

  TIM_ClockConfigTypeDef sClockSourceConfig = {0};
  TIM_MasterConfigTypeDef sMasterConfig = {0};
  TIM_OC_InitTypeDef sConfigOC = {0};
  TIM_BreakDeadTimeConfigTypeDef sBreakDeadTimeConfig = {0};

  htim1.Instance = TIM1;
  htim1.Init.Prescaler = 17999;
  htim1.Init.CounterMode = TIM_COUNTERMODE_UP;
  htim1.Init.Period = 15;
  htim1.Init.ClockDivision = TIM_CLOCKDIVISION_DIV1;
  htim1.Init.RepetitionCounter = 0;
  htim1.Init.AutoReloadPreload = TIM_AUTORELOAD_PRELOAD_ENABLE;
  if (HAL_TIM_Base_Init(&htim1) != HAL_OK)
  {
    Error_Handler();
  }
  sClockSourceConfig.ClockSource = TIM_CLOCKSOURCE_INTERNAL;
  if (HAL_TIM_ConfigClockSource(&htim1, &sClockSourceConfig) != HAL_OK)
  {
    Error_Handler();
  }
  if (HAL_TIM_PWM_Init(&htim1) != HAL_OK)
  {
    Error_Handler();
  }
  sMasterConfig.MasterOutputTrigger = TIM_TRGO_RESET;
  sMasterConfig.MasterSlaveMode = TIM_MASTERSLAVEMODE_DISABLE;
  if (HAL_TIMEx_MasterConfigSynchronization(&htim1, &sMasterConfig) != HAL_OK)
  {
    Error_Handler();
  }
  sConfigOC.OCMode = TIM_OCMODE_PWM1;
  sConfigOC.Pulse = 0;
  sConfigOC.OCPolarity = TIM_OCPOLARITY_HIGH;
  sConfigOC.OCNPolarity = TIM_OCNPOLARITY_LOW;
  sConfigOC.OCFastMode = TIM_OCFAST_DISABLE;
  sConfigOC.OCIdleState = TIM_OCIDLESTATE_RESET;
  sConfigOC.OCNIdleState = TIM_OCNIDLESTATE_SET;
  if (HAL_TIM_PWM_ConfigChannel(&htim1, &sConfigOC, TIM_CHANNEL_1) != HAL_OK)
  {
    Error_Handler();
  }
  if (HAL_TIM_PWM_ConfigChannel(&htim1, &sConfigOC, TIM_CHANNEL_2) != HAL_OK)
  {
    Error_Handler();
  }
  if (HAL_TIM_PWM_ConfigChannel(&htim1, &sConfigOC, TIM_CHANNEL_3) != HAL_OK)
  {
    Error_Handler();
  }
  sBreakDeadTimeConfig.OffStateRunMode = TIM_OSSR_DISABLE;
  sBreakDeadTimeConfig.OffStateIDLEMode = TIM_OSSI_DISABLE;
  sBreakDeadTimeConfig.LockLevel = TIM_LOCKLEVEL_OFF;
  sBreakDeadTimeConfig.DeadTime = 0;
  sBreakDeadTimeConfig.BreakState = TIM_BREAK_DISABLE;
  sBreakDeadTimeConfig.BreakPolarity = TIM_BREAKPOLARITY_HIGH;
  sBreakDeadTimeConfig.AutomaticOutput = TIM_AUTOMATICOUTPUT_DISABLE;
  if (HAL_TIMEx_ConfigBreakDeadTime(&htim1, &sBreakDeadTimeConfig) != HAL_OK)
  {
    Error_Handler();
  }
  HAL_TIM_MspPostInit(&htim1);

}

static void MX_TIM2_Init(void)
{

  TIM_ClockConfigTypeDef sClockSourceConfig = {0};
  TIM_MasterConfigTypeDef sMasterConfig = {0};
  TIM_IC_InitTypeDef sConfigIC = {0};

  htim2.Instance = TIM2;
  htim2.Init.Prescaler = 143;
  htim2.Init.CounterMode = TIM_COUNTERMODE_UP;
  htim2.Init.Period = 65535;
  htim2.Init.ClockDivision = TIM_CLOCKDIVISION_DIV1;
  htim2.Init.AutoReloadPreload = TIM_AUTORELOAD_PRELOAD_DISABLE;
  if (HAL_TIM_Base_Init(&htim2) != HAL_OK)
  {
    Error_Handler();
  }
  sClockSourceConfig.ClockSource = TIM_CLOCKSOURCE_INTERNAL;
  if (HAL_TIM_ConfigClockSource(&htim2, &sClockSourceConfig) != HAL_OK)
  {
    Error_Handler();
  }
  if (HAL_TIM_IC_Init(&htim2) != HAL_OK)
  {
    Error_Handler();
  }
  sMasterConfig.MasterOutputTrigger = TIM_TRGO_RESET;
  sMasterConfig.MasterSlaveMode = TIM_MASTERSLAVEMODE_DISABLE;
  if (HAL_TIMEx_MasterConfigSynchronization(&htim2, &sMasterConfig) != HAL_OK)
  {
    Error_Handler();
  }
  sConfigIC.ICPolarity = TIM_INPUTCHANNELPOLARITY_FALLING;
  sConfigIC.ICSelection = TIM_ICSELECTION_DIRECTTI;
  sConfigIC.ICPrescaler = TIM_ICPSC_DIV1;
  sConfigIC.ICFilter = 8;
  if (HAL_TIM_IC_ConfigChannel(&htim2, &sConfigIC, TIM_CHANNEL_1) != HAL_OK)
  {
    Error_Handler();
  }
  sConfigIC.ICPolarity = TIM_INPUTCHANNELPOLARITY_RISING;
  sConfigIC.ICSelection = TIM_ICSELECTION_INDIRECTTI;
  sConfigIC.ICFilter = 0;
  if (HAL_TIM_IC_ConfigChannel(&htim2, &sConfigIC, TIM_CHANNEL_2) != HAL_OK)
  {
    Error_Handler();
  }

}

static void MX_TIM3_Init(void)
{

  TIM_ClockConfigTypeDef sClockSourceConfig = {0};
  TIM_MasterConfigTypeDef sMasterConfig = {0};
  TIM_IC_InitTypeDef sConfigIC = {0};

  htim3.Instance = TIM3;
  htim3.Init.Prescaler = 71;
  htim3.Init.CounterMode = TIM_COUNTERMODE_UP;
  htim3.Init.Period = 40000;
  htim3.Init.ClockDivision = TIM_CLOCKDIVISION_DIV1;
  htim3.Init.AutoReloadPreload = TIM_AUTORELOAD_PRELOAD_DISABLE;
  if (HAL_TIM_Base_Init(&htim3) != HAL_OK)
  {
    Error_Handler();
  }
  sClockSourceConfig.ClockSource = TIM_CLOCKSOURCE_INTERNAL;
  if (HAL_TIM_ConfigClockSource(&htim3, &sClockSourceConfig) != HAL_OK)
  {
    Error_Handler();
  }
  if (HAL_TIM_IC_Init(&htim3) != HAL_OK)
  {
    Error_Handler();
  }
  sMasterConfig.MasterOutputTrigger = TIM_TRGO_RESET;
  sMasterConfig.MasterSlaveMode = TIM_MASTERSLAVEMODE_DISABLE;
  if (HAL_TIMEx_MasterConfigSynchronization(&htim3, &sMasterConfig) != HAL_OK)
  {
    Error_Handler();
  }
  sConfigIC.ICPolarity = TIM_INPUTCHANNELPOLARITY_FALLING;
  sConfigIC.ICSelection = TIM_ICSELECTION_DIRECTTI;
  sConfigIC.ICPrescaler = TIM_ICPSC_DIV1;
  sConfigIC.ICFilter = 0;
  if (HAL_TIM_IC_ConfigChannel(&htim3, &sConfigIC, TIM_CHANNEL_1) != HAL_OK)
  {
    Error_Handler();
  }
  sConfigIC.ICPolarity = TIM_INPUTCHANNELPOLARITY_RISING;
  sConfigIC.ICSelection = TIM_ICSELECTION_INDIRECTTI;
  if (HAL_TIM_IC_ConfigChannel(&htim3, &sConfigIC, TIM_CHANNEL_2) != HAL_OK)
  {
    Error_Handler();
  }

}

static void MX_TIM4_Init(void)
{

  TIM_ClockConfigTypeDef sClockSourceConfig = {0};
  TIM_MasterConfigTypeDef sMasterConfig = {0};
  TIM_OC_InitTypeDef sConfigOC = {0};

  htim4.Instance = TIM4;
  htim4.Init.Prescaler = 359;
  htim4.Init.CounterMode = TIM_COUNTERMODE_UP;
  htim4.Init.Period = 99;
  htim4.Init.ClockDivision = TIM_CLOCKDIVISION_DIV1;
  htim4.Init.AutoReloadPreload = TIM_AUTORELOAD_PRELOAD_ENABLE;
  if (HAL_TIM_Base_Init(&htim4) != HAL_OK)
  {
    Error_Handler();
  }
  sClockSourceConfig.ClockSource = TIM_CLOCKSOURCE_INTERNAL;
  if (HAL_TIM_ConfigClockSource(&htim4, &sClockSourceConfig) != HAL_OK)
  {
    Error_Handler();
  }
  if (HAL_TIM_PWM_Init(&htim4) != HAL_OK)
  {
    Error_Handler();
  }
  sMasterConfig.MasterOutputTrigger = TIM_TRGO_RESET;
  sMasterConfig.MasterSlaveMode = TIM_MASTERSLAVEMODE_DISABLE;
  if (HAL_TIMEx_MasterConfigSynchronization(&htim4, &sMasterConfig) != HAL_OK)
  {
    Error_Handler();
  }
  sConfigOC.OCMode = TIM_OCMODE_PWM1;
  sConfigOC.Pulse = 0;
  sConfigOC.OCPolarity = TIM_OCPOLARITY_HIGH;
  sConfigOC.OCFastMode = TIM_OCFAST_DISABLE;
  if (HAL_TIM_PWM_ConfigChannel(&htim4, &sConfigOC, TIM_CHANNEL_1) != HAL_OK)
  {
    Error_Handler();
  }
  if (HAL_TIM_PWM_ConfigChannel(&htim4, &sConfigOC, TIM_CHANNEL_2) != HAL_OK)
  {
    Error_Handler();
  }
  HAL_TIM_MspPostInit(&htim4);

}

static void MX_USART1_UART_Init(void)
{

  huart1.Instance = USART1;
  huart1.Init.BaudRate = 115200;
  huart1.Init.WordLength = UART_WORDLENGTH_8B;
  huart1.Init.StopBits = UART_STOPBITS_1;
  huart1.Init.Parity = UART_PARITY_NONE;
  huart1.Init.Mode = UART_MODE_TX_RX;
  huart1.Init.HwFlowCtl = UART_HWCONTROL_NONE;
  huart1.Init.OverSampling = UART_OVERSAMPLING_16;
  if (HAL_UART_Init(&huart1) != HAL_OK)
  {
    Error_Handler();
  }

}

static void MX_DMA_Init(void)
{

  /* DMA controller clock enable */
  __HAL_RCC_DMA1_CLK_ENABLE();

}

static void MX_GPIO_Init(void)
{
  GPIO_InitTypeDef GPIO_InitStruct = {0};

  /* GPIO Ports Clock Enable */
  __HAL_RCC_GPIOC_CLK_ENABLE();
  __HAL_RCC_GPIOD_CLK_ENABLE();
  __HAL_RCC_GPIOA_CLK_ENABLE();
  __HAL_RCC_GPIOB_CLK_ENABLE();

  /*Configure GPIO pin Output Level */
  HAL_GPIO_WritePin(GPIOC, TOP_HEATER_EN_Pin|nCHARGE_SHUNT_Pin|REMOTE_LAMP_EN_Pin, GPIO_PIN_RESET);

  /*Configure GPIO pin Output Level */
  HAL_GPIO_WritePin(GPIOB, Test_Prob1_Pin|Test_Prob2_Pin|BATTERY_PSU_EN_Pin|BOTTOM_HEATER_EN_Pin
                          |nRF_RST_Pin, GPIO_PIN_RESET);

  /*Configure GPIO pin Output Level */
  HAL_GPIO_WritePin(nUSB_EN_GPIO_Port, nUSB_EN_Pin, GPIO_PIN_RESET);

  /*Configure GPIO pins : TOP_HEATER_EN_Pin nCHARGE_SHUNT_Pin REMOTE_LAMP_EN_Pin */
  GPIO_InitStruct.Pin = TOP_HEATER_EN_Pin|nCHARGE_SHUNT_Pin|REMOTE_LAMP_EN_Pin;
  GPIO_InitStruct.Mode = GPIO_MODE_OUTPUT_PP;
  GPIO_InitStruct.Pull = GPIO_PULLDOWN;
  GPIO_InitStruct.Speed = GPIO_SPEED_FREQ_LOW;
  HAL_GPIO_Init(GPIOC, &GPIO_InitStruct);

  /*Configure GPIO pins : Test_Prob1_Pin Test_Prob2_Pin */
  GPIO_InitStruct.Pin = Test_Prob1_Pin|Test_Prob2_Pin;
  GPIO_InitStruct.Mode = GPIO_MODE_OUTPUT_PP;
  GPIO_InitStruct.Pull = GPIO_NOPULL;
  GPIO_InitStruct.Speed = GPIO_SPEED_FREQ_MEDIUM;
  HAL_GPIO_Init(GPIOB, &GPIO_InitStruct);

  /*Configure GPIO pins : BATTERY_PSU_EN_Pin BOTTOM_HEATER_EN_Pin nRF_RST_Pin */
  GPIO_InitStruct.Pin = BATTERY_PSU_EN_Pin|BOTTOM_HEATER_EN_Pin|nRF_RST_Pin;
  GPIO_InitStruct.Mode = GPIO_MODE_OUTPUT_PP;
  GPIO_InitStruct.Pull = GPIO_NOPULL;
  GPIO_InitStruct.Speed = GPIO_SPEED_FREQ_LOW;
  HAL_GPIO_Init(GPIOB, &GPIO_InitStruct);

  /*Configure GPIO pin : nUSB_EN_Pin */
  GPIO_InitStruct.Pin = nUSB_EN_Pin;
  GPIO_InitStruct.Mode = GPIO_MODE_OUTPUT_PP;
  GPIO_InitStruct.Pull = GPIO_NOPULL;
  GPIO_InitStruct.Speed = GPIO_SPEED_FREQ_LOW;
  HAL_GPIO_Init(nUSB_EN_GPIO_Port, &GPIO_InitStruct);

  /*Configure GPIO pin : RF_INT_Pin */
  GPIO_InitStruct.Pin = RF_INT_Pin;
  GPIO_InitStruct.Mode = GPIO_MODE_IT_RISING;
  GPIO_InitStruct.Pull = GPIO_NOPULL;
  HAL_GPIO_Init(RF_INT_GPIO_Port, &GPIO_InitStruct);

  /*Configure GPIO pin : TEST_BUTTON_Pin */
  GPIO_InitStruct.Pin = TEST_BUTTON_Pin;
  GPIO_InitStruct.Mode = GPIO_MODE_IT_FALLING;
  GPIO_InitStruct.Pull = GPIO_NOPULL;
  HAL_GPIO_Init(TEST_BUTTON_GPIO_Port, &GPIO_InitStruct);

  /* EXTI interrupt init*/
  HAL_NVIC_SetPriority(EXTI3_IRQn, 1, 0);
  HAL_NVIC_EnableIRQ(EXTI3_IRQn);

  HAL_NVIC_SetPriority(EXTI9_5_IRQn, 2, 0);
  HAL_NVIC_EnableIRQ(EXTI9_5_IRQn);

}

/* USER CODE BEGIN 4 */

// For local LAMP

void Lamp_ctrl(FunctionalState EN, uint8_t LAMP_WATT)
{
  if (EN != 0)
  {
	uint8_t walt = LAMP_WATT;
	uint8_t lamp_level;
	uint8_t i;
	switch (walt)
	{
	  case 0:      {lamp_level = 0;               break;}
	  case _4W: 	{lamp_level = LAMP_LEVEL_4W;   break;}
	  case _8W: 	{lamp_level = LAMP_LEVEL_8W;   break;}
	  case _16W: 	{lamp_level = LAMP_LEVEL_16W;  break;}
	  default:     {                              break;}
	}

	Lamp_Diming_cnt = lamp_level*4/10;        // calculate that how many times the diming operation will decrease the PWM level on 60% final level
	Lamp_Diming_timer = 180/Lamp_Diming_cnt;	 // the total diming period elapsed 3min(180s), calculate the diming will decrese the level by 1
	Lamp_Diming_level =	lamp_level;               // load the initial lamp level value to diming control variable

	HAL_GPIO_WritePin(nCHARGE_SHUNT_GPIO_Port,nCHARGE_SHUNT_Pin,GPIO_PIN_SET);  // disable shunt resister

	for ( i=0; i< lamp_level; i++)
	{
	  __HAL_TIM_SetCompare(&htim4, LAMP_PWM_CH, i); // the LAMP_LEVEL controls the brightness, value range 0-99, represent n/100 of full power
	  HAL_Delay(2);
	}
  }
  else
  {
    HAL_GPIO_WritePin(nCHARGE_SHUNT_GPIO_Port,nCHARGE_SHUNT_Pin,GPIO_PIN_RESET);  // enable shunt resister
    __HAL_TIM_SetCompare(&htim4, LAMP_PWM_CH, 0);
  }
}

void Lamp_Diming(void)
{
  if (Emergency_ElapsedTime == (DIMING_START_TIME -1))
  {
    Lamp_Diming_startTime = Emergency_ElapsedTime;
  }

  if ((Emergency_ElapsedTime >= DIMING_START_TIME ) && (Emergency_ElapsedTime < (DIMING_START_TIME + 180 ))) // starts at 2nd min and stops at 11th min (15 min is 900s)
  {
    Lamp_Dimng_elapsedTime = Emergency_ElapsedTime - Lamp_Diming_startTime;
    if (Lamp_Dimng_elapsedTime == Lamp_Diming_timer)
    {
      if ( Lamp_Diming_level !=0 )
	 {
	   Lamp_Diming_level--;  // in case the zero watt lamp installed
   	 }
      __HAL_TIM_SetCompare(&htim4, LAMP_PWM_CH, Lamp_Diming_level);

   	 Lamp_Diming_startTime = Emergency_ElapsedTime ;                  // reload the timer
    }
  }
}

// Remote LAMP
void Remote_Lamp_EN(FunctionalState EN)
{
  if (EN != 0)
  {
    HAL_GPIO_WritePin(nCHARGE_SHUNT_GPIO_Port,nCHARGE_SHUNT_Pin,GPIO_PIN_SET);      // disable shunt resister
    HAL_GPIO_WritePin(REMOTE_LAMP_EN_GPIO_Port,REMOTE_LAMP_EN_Pin,GPIO_PIN_SET);    //Enable remote lamp power
  }
  else
  {
    HAL_GPIO_WritePin(nCHARGE_SHUNT_GPIO_Port,nCHARGE_SHUNT_Pin,GPIO_PIN_RESET);    // enable shunt resister
    HAL_GPIO_WritePin(REMOTE_LAMP_EN_GPIO_Port,REMOTE_LAMP_EN_Pin,GPIO_PIN_RESET);  //Disable remote lamp power
  }
}

/*
#define Temp_No_Batt          3840(0xF00)  // no battery is installed
#define Temp_5         		2870(0xB36)  // 5°C the temperature heater is turning on at full power
#define Temp_20        		2250(0x8CA)  // 20°C   Cheater is turned off
#define Temp_40             	1500(0x5DC)  // 40°C   CC-charge state is not allowed
#define Temp_80              	580 (0x244)  // 80°C   hot the charge needs to be turned off

*/

// the two heater will be turned on at  the same time on the EVO V3.5 and higer version board which equipped with 60W power supply
void HEATER_task(void)
{
  if (NV_Profile_Runtime.HasHeater != 0 ) // System_State_Machine == STANDBY
  {

    if (( System_State_Machine == STANDBY ) && (System_time.Sec >1))
    {
    // for buttom battery pack
      if (  Batt_Temperature[0] != No_Battery )
      {
	   switch (Heater_state[0])
	   {
	     case Heater_Off:
	     {
	       if ( Batt_Temperature[0] == TEMP_IS_Cool)
	       {
		    HAL_GPIO_WritePin(BOTTOM_HEATER_EN_GPIO_Port, BOTTOM_HEATER_EN_Pin, GPIO_PIN_SET); // turn on bottom heater

		    Heater_state[0] = On_Heating;
		    LED_task(Heating, ENABLE);

	       }
	       break;
	     }

	     case On_Heating:
	     {
	       if ( (Batt_Temperature[0]  == TEMP_IS_Warm) || (Batt_Temperature[0]  == TEMP_IS_Hot) ) // heated to the enough temperature and heating is complete
	       {
		    HAL_GPIO_WritePin(BOTTOM_HEATER_EN_GPIO_Port, BOTTOM_HEATER_EN_Pin, GPIO_PIN_RESET); // turn off the heater
 		    Heater_state[0] = Heater_Off;

		    if (Heater_state[1] != On_Heating)
		    {
		      LED_task(Heating, DISABLE);
		    }
	       }
	       break;
	     }

	     default:
	     {
		   HAL_GPIO_WritePin(BOTTOM_HEATER_EN_GPIO_Port, BOTTOM_HEATER_EN_Pin, GPIO_PIN_RESET);
		   Heater_state[0] = Heater_Off;
		   if (Heater_state[1] != On_Heating)
		   {
		     LED_task(Heating, DISABLE);
		   }
		   break;
	     }
        }
      }
      else // buttom battery not installed or removed
      {
	   HAL_GPIO_WritePin(BOTTOM_HEATER_EN_GPIO_Port, BOTTOM_HEATER_EN_Pin, GPIO_PIN_RESET);
	   Heater_state[0] = Heater_Off;
	   if (Heater_state[1] != On_Heating)
	   {
	     LED_task(Heating, DISABLE);
	   }
      }

//		top battery pack,
	 if (Batt_Temperature[1] != No_Battery)
	 {
	   switch (Heater_state[1])
	   {
	     case Heater_Off:
	     {
		  if ( Batt_Temperature[1] == TEMP_IS_Cool)
		  {
              HAL_GPIO_WritePin(TOP_HEATER_EN_GPIO_Port, TOP_HEATER_EN_Pin, GPIO_PIN_SET);       // turn on top heater

		    Heater_state[1] = On_Heating;
		    LED_task(Heating, ENABLE);
		  }
		  break;
	     }

	     case On_Heating:
	     {
		  if ((Batt_Temperature[1]  == TEMP_IS_Warm) || (Batt_Temperature[1]  == TEMP_IS_Hot) ) // heated to the enough temperature and heating is complete
		  {
		    HAL_GPIO_WritePin(TOP_HEATER_EN_GPIO_Port, TOP_HEATER_EN_Pin, GPIO_PIN_RESET);        // turn off top heater
		    Heater_state[1] = Heater_Off;
		    if (Heater_state[0] != On_Heating)
		    {
			 LED_task(Heating, DISABLE);
		    }
		  }
		  break;
	     }

	     default:
	     {
		  HAL_GPIO_WritePin(TOP_HEATER_EN_GPIO_Port, TOP_HEATER_EN_Pin, GPIO_PIN_RESET);
		  Heater_state[1] = Heater_Off;
		  if (Heater_state[0] != On_Heating)
	       {
	         LED_task(Heating, DISABLE);
	       }
		  break;
	     }
	   }
	 }
	 else  // top battery not installed or removed
	 {
	   HAL_GPIO_WritePin(TOP_HEATER_EN_GPIO_Port, TOP_HEATER_EN_Pin, GPIO_PIN_RESET);
	   Heater_state[1] = Heater_Off;
	   if (Heater_state[0] != On_Heating)
	   {
	     LED_task(Heating, DISABLE);
	   }
	 }
    }
    else   // in all the state other than STANDBY will clear the heaters
    {

	   HAL_GPIO_WritePin(BOTTOM_HEATER_EN_GPIO_Port, BOTTOM_HEATER_EN_Pin, GPIO_PIN_RESET); // turn off heaters
        HAL_GPIO_WritePin(TOP_HEATER_EN_GPIO_Port,    TOP_HEATER_EN_Pin,    GPIO_PIN_RESET);
        Heater_state[0] = Heater_Off;
        Heater_state[1] = Heater_Off;
	   LED_task(Heating, DISABLE);
    }

  }
  else     // unit has no heater installed
  {
     HAL_GPIO_WritePin(BOTTOM_HEATER_EN_GPIO_Port, BOTTOM_HEATER_EN_Pin, GPIO_PIN_RESET); // turn off heaters
     HAL_GPIO_WritePin(TOP_HEATER_EN_GPIO_Port,    TOP_HEATER_EN_Pin,    GPIO_PIN_RESET);
     Heater_state[0] = Heater_Off;
     Heater_state[1] = Heater_Off;
     LED_task(Heating, DISABLE);
/*
	if (( Batt_Temperature[0] == TEMP_IS_Cold ) || (Batt_Temperature[1] == TEMP_IS_Cold ) )
     {
	  LED_task(Batt_Cold, ENABLE);
	}
	else
	{
	  LED_task(Batt_Cold, DISABLE);
	}
  */
  }

}

// For Test button GPIO interrupt

Button_Progress_TypeDef Button_Porgress = Button_Progress_Complete;

uint32_t Button_Press_StartTime = 0;
uint32_t Button_Press_Duration = 0;
uint8_t  tap_cnt = 0;
uint8_t  hold_registed = 0;
uint32_t temp_time;

void HAL_GPIO_EXTI_Callback(uint16_t GPIO_Pin)
{
  if(GPIO_Pin == TEST_BUTTON_Pin)
  {
   	Button_Porgress = Button_in_Progress;
  	tap_cnt =0;
 // 	 HAL_GPIO_WritePin(Test_Prob_GPIO_Port,Test_Prob_Pin,GPIO_PIN_SET);  //testing flag
  	while (Button_Porgress == Button_in_Progress )
  	{
  	   Button_Press_StartTime = HAL_GetTick();   // timing start
  	   while(HAL_GPIO_ReadPin( TEST_BUTTON_GPIO_Port, TEST_BUTTON_Pin) == 0 ) // check the press period
        {
//HAL_GPIO_WritePin(Test_Prob_GPIO_Port,Test_Prob_Pin,GPIO_PIN_SET);  //testing flag
	     temp_time = HAL_GetTick();
	     if ( temp_time >= Button_Press_StartTime )
	     {
	       Button_Press_Duration = HAL_GetTick() - Button_Press_StartTime;
	     }
	     else
	     {
		  Button_Press_Duration = UINT32_MAX + HAL_GetTick() - Button_Press_StartTime + 1;
	     }
        }
//HAL_GPIO_WritePin(Test_Prob_GPIO_Port,Test_Prob_Pin,GPIO_PIN_RESET);  //testing flag

  	   if ((Button_Press_Duration < Button_ShortTap_TimeMax) || (Button_Press_Duration >= Button_Press_TimeOut))    // too short or too long ingnor
  	   {
  		tap_cnt =0;
  	   }
  	   else if ((Button_Press_Duration >= Button_ShortTap_TimeMax) &&( Button_Press_Duration < Button_Tap_TimeMax))
  	   {
  		tap_cnt++;
  	   }
  	   else if ((Button_Press_Duration >= Button_Tap_TimeMax) && (Button_Press_Duration < Button_Hold_TimeMin))
  	   {
  		hold_registed = Short_Hold;
  	   }
  	   else
  	   {
  		hold_registed = Long_Hold;
  	   }

  	   Button_Press_Duration =0;
	   HAL_Delay(5);
	   Button_Press_StartTime = HAL_GetTick();   // timing start

  	   while (Button_Press_Duration < Button_Release_TimeMax)       //	 check the release time period for 300ms
  	   {
          temp_time = HAL_GetTick();
	     Button_Press_Duration = temp_time - Button_Press_StartTime;
  	     if (HAL_GPIO_ReadPin( TEST_BUTTON_GPIO_Port, TEST_BUTTON_Pin) == 0)	 // next press detect
  	     {
  		  Button_Porgress = Button_in_Progress;
  		  break;
  	     }
	     else
	     {
		  Button_Porgress = Button_Progress_Complete;
	     }
  	   }

  	}

  	if((hold_registed != Short_Hold) && (hold_registed != Long_Hold))
  	{
  	  if      (tap_cnt ==1) {TEST_Button = Single_Tap;}
  	  else if (tap_cnt ==2) {TEST_Button = Double_Tap;}
       else if (tap_cnt ==3) {TEST_Button = Triple_Tap;}
       else if (tap_cnt ==4) {TEST_Button = Quad_Tap;}
  	  else                  {TEST_Button = Idle;}
  	}
	else if (hold_registed == Short_Hold)
	{
  	  if      (tap_cnt ==0) {TEST_Button = Short_Hold;}
       else if (tap_cnt ==1) {TEST_Button = Single_Tap_Short_Hold;}
  	  else if (tap_cnt ==2) {TEST_Button = Double_Tap_Short_Hold;}
       else if (tap_cnt ==3) {TEST_Button = Triple_Tap_Short_Hold;}
       else if (tap_cnt ==4) {TEST_Button = Quad_Tap_Short_Hold;}
  	  else                  {TEST_Button = Idle;}
  	}
	else if (hold_registed == Long_Hold)
	{
  	  if      (tap_cnt ==0) {TEST_Button = Long_Hold;}
       else if (tap_cnt ==1) {TEST_Button = Single_Tap_Long_Hold;}
  	  else if (tap_cnt ==2) {TEST_Button = Double_Tap_Long_Hold;}
       else if (tap_cnt ==3) {TEST_Button = Triple_Tap_Long_Hold;}
       else if (tap_cnt ==4) {TEST_Button = Quad_Tap_Long_Hold;}
  	  else                  {TEST_Button = Idle;}
  	}

  	tap_cnt =0;
	hold_registed = 0;
  }

  __HAL_GPIO_EXTI_CLEAR_IT(GPIO_Pin); // reset IRQ flag

}

void Button_task(void)
{
  switch (System_State_Machine)
  {
    case STANDBY:
    {
     switch (TEST_Button)
	{
	  case Idle:
	  {
		break;
	  }
  	  case Single_Tap:
       {
         Lamp_ctrl(ENABLE, NV_Profile_Runtime.HeadWattage);
         Remote_Lamp_EN(ENABLE);

         System_State_Machine = SHORT_TEST;
         TEST_Button = Idle;

         LED_task(_30s_TEST,ENABLE);
         time_stamp_start = System_time.Sec;
	    Charger_ElapsedTime = 0;
         Charger_StartTime = HAL_GetTick() ;
         ADC_StartTime = HAL_GetTick() ;             //get the starting time to start ADC: unit second
         break;
       }
	  case Double_Tap:
	  case Triple_Tap:
	  case Quad_Tap:
	  case Short_Hold:
	  {
	    TEST_Button = Idle;
	    break;
	  }
	  case Long_Hold:
       {
         if(( CHR_Stage == RC_CHR) || ( CHR_Stage == Termination_CHR))   // battery is full to run the long test
	    {
		 Lamp_ctrl(ENABLE, NV_Profile_Runtime.HeadWattage);
     	 Remote_Lamp_EN(ENABLE);

     	 System_State_Machine = LONG_TEST;

     	 LED_task(_90M_TEST,ENABLE);
     	 NV_Profile_Runtime.LastTestFailedFlag =1;
     	 Flash_write();

		 time_stamp_start = System_time.Sec;
		 Charger_ElapsedTime = 0;
		 Charger_StartTime = HAL_GetTick() ;
     	 ADC_StartTime = HAL_GetTick() ;      //get the starting time to start ADC
	    }
	    else if ( CHR_Stage == IDL_CHR )      // battery is bad needs to be replaced, no need to do the test
	    {                                      // set the long test failure flag
		 System_time.Period = 0;
		 LED_task( Low_Capacity,ENABLE);
		 NV_Profile_Runtime.LastTestFailedFlag = 1;
		 Flash_write();
	    }
		 LED_task(IR_Signal,ENABLE);
		 TEST_Button = Idle;
		 break;
       }
       case Single_Tap_Short_Hold:
	  case Double_Tap_Short_Hold:
	  {
	    TEST_Button = Idle;
	    break;
	  }
	  case Triple_Tap_Short_Hold:
	  {
	    TEST_Button = Idle;
	    NV_Profile_Runtime.LastTestFailedFlag = 0;
	    Flash_write();
	    NVIC_SystemReset();
         break;
       }
	  case Quad_Tap_Short_Hold:
       case Single_Tap_Long_Hold:
	  case Double_Tap_Long_Hold:
	  case Triple_Tap_Long_Hold:
	  case Quad_Tap_Long_Hold:
       {
	    TEST_Button = Idle;
	    break;
	  }
	  default:
	    break;
	}

	break;
     }

	case EMERGENCY:
	{
	  TEST_Button = Idle;
	  break;
	}

	case SHORT_TEST:
	case LONG_TEST:
	{
	  if (TEST_Button != Idle)
	  {
	    TEST_Button = Idle;
	    Lamp_ctrl(DISABLE, 0);  // turn off the lamps return to standby
  	    Remote_Lamp_EN(DISABLE);

	    LED_task(_30s_TEST, DISABLE);
	    LED_task(_90M_TEST, DISABLE);
	    LED_task(Low_Capacity, DISABLE);

	    NV_Profile_Runtime.LastTestFailedFlag =0;
	    Flash_write();

	    Charger_ElapsedTime = 0;
	    Charger_StartTime = HAL_GetTick();
	    System_State_Machine = STANDBY;
	  }
	   break;
	 }
	 default:
        break;
  }
}

// For scheduler

int16_t delta;

uint32_t time_delta(uint32_t Current_time, uint32_t start_time)
{
  delta = Current_time - start_time;
  if (delta < 0)
  {
    delta = (UINT32_MAX/1000) + Current_time - start_time + 1; // *nan should be 86400
  }
  return delta;
}

uint16_t time_temp =0;

void Scheduler_task(void)
{
  if ( Short_test_En == 1)
  {
    Short_test_En = 0;                  // clear the short test active flag

    Lamp_ctrl(ENABLE, NV_Profile_Runtime.HeadWattage);
    Remote_Lamp_EN(ENABLE);

    System_State_Machine = SHORT_TEST;

    time_stamp_start = System_time.Sec;

    LED_task(_30s_TEST,ENABLE);
    System_State_Machine = SHORT_TEST;
    ADC_StartTime = HAL_GetTick() ;
  }

  if ( Long_test_En == 1)
  {
    ADC_batt_reading = ADC_DMA_VALUE[ADC_BATT_VOLTAGE];
    if ( ( CHR_Stage == RC_CHR) || (  CHR_Stage == Termination_CHR))    // the battery is full to do the long test or wait until it is fully charged
    {
	 Lamp_ctrl(ENABLE, NV_Profile_Runtime.HeadWattage);
	 Remote_Lamp_EN(ENABLE);

	 time_stamp_start = System_time.Sec;
	 Long_test_En = 0;                          // clear the long test active flag
	 LED_task(_90M_TEST,ENABLE);

	 System_time.Period = 0;
	 System_time.Day = 0;
	 System_State_Machine = LONG_TEST;
	 NV_Profile_Runtime.LastTestFailedFlag =1;   // write the long test flag
	 Flash_write();
      ADC_StartTime = HAL_GetTick() ;
    }
    else if (CHR_Stage == IDL_CHR )             // battery is bad, no need to do the test but set the failure flag
    {
	 System_time.Period = 0;
	 System_time.Day = 0;
	 Long_test_En = 0;
	 NV_Profile_Runtime.LastTestFailedFlag =1;   // write the long test flag
	 Flash_write();
    }

  }

}

uint32_t ElapsedTimer_ADC(uint32_t start_time)
{
  uint32_t current_time = HAL_GetTick();
  if ( current_time >= start_time)
  {
    return current_time - start_time;
  }
  else
  {
    return (UINT32_MAX - start_time + current_time +1) ;
  }
}

uint32_t ElapsedTimer_TimeDelay(uint32_t start_time) // the start_time is in ms but the result unit is in second
{
 uint32_t current_time = HAL_GetTick();
 return  (current_time - start_time)/1000;          // No need to handle overflow explicitly

}

/*********************************************************************************************************/

/* USER CODE END 4 */

void Error_Handler(void)
{
  __disable_irq();
  while (1)
  {
  }
}
